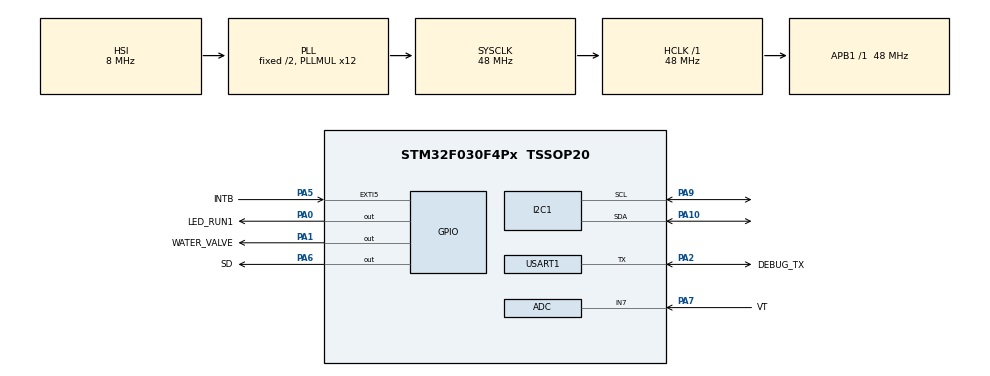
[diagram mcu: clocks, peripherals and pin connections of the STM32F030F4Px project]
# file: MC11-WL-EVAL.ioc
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Mcu.Family=STM32F0
Mcu.Name=STM32F030F4Px
Mcu.Package=TSSOP20
PA0.GPIO_Label=LED_RUN1
PA0.Signal=GPIO_Output
PA1.GPIO_Label=WATER_VALVE
PA1.Signal=GPIO_Output
PA10.Mode=I2C
PA10.Signal=I2C1_SDA
PA13.Mode=Serial_Wire
PA13.Signal=SYS_SWDIO
PA14.Mode=Serial_Wire
PA14.Signal=SYS_SWCLK
PA2.GPIO_Label=DEBUG_TX
PA2.Mode=Half_duplex(single_wire_mode)
PA2.Signal=USART1_TX
PA5.GPIO_Label=INTB
PA5.Signal=GPXTI5
PA6.GPIO_Label=SD
PA6.PinState=GPIO_PIN_SET
PA6.Signal=GPIO_Output
PA7.GPIO_Label=VT
PA7.Mode=IN7
PA7.Signal=ADC_IN7
PA9.Mode=I2C
PA9.Signal=I2C1_SCL
ProjectManager.HeapSize=0x200
ProjectManager.StackSize=0x400
ProjectManager.TargetToolchain=MDK-ARM V5
RCC.AHBFreq_Value=48000000
RCC.APB1Freq_Value=48000000
RCC.APB1TimFreq_Value=48000000
RCC.HCLKFreq_Value=48000000
RCC.PLLMUL=RCC_PLL_MUL12
RCC.SYSCLKFreq_VALUE=48000000
RCC.SYSCLKSource=RCC_SYSCLKSOURCE_PLLCLK
USART1.BaudRate=9600
USART1.VirtualMode-Half_duplex(single_wire_mode)=VM_ASYNC
board=custom

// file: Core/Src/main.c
/* USER CODE BEGIN Header */
/**
  ******************************************************************************
  * @file           : main.c
  * @brief          : Main program body
  ******************************************************************************
  * @attention
  *
  * Copyright (c) 2024 STMicroelectronics.
  * All rights reserved.
  *
  * This software is licensed under terms that can be found in the LICENSE file
  * in the root directory of this software component.
  * If no LICENSE file comes with this software, it is provided AS-IS.
  *
  ******************************************************************************
  */
/* USER CODE END Header */
#include "main.h"
#include "adc.h"
#include "i2c.h"
#include "usart.h"
#include "gpio.h"

/* USER CODE BEGIN Includes */
#include <stdio.h>
#include "mc11.h"
/* USER CODE END Includes */

/* USER CODE BEGIN PV */
/*打印开关print_en在MC11.h文件中定义，当前定义为0，打印功能关闭，定义为1打印功能开启*/
int wait_time=0;
float F0,F1,C;//通道0/1频率值，电容值
uint8_t result = 0;
/* USER CODE END PV */

void SystemClock_Config(void);

int main(void)
{

  /* MCU Configuration--------------------------------------------------------*/

  /* Reset of all peripherals, Initializes the Flash interface and the Systick. */
  HAL_Init();

  /* Configure the system clock */
  SystemClock_Config();

  /* Initialize all configured peripherals */
  MX_GPIO_Init();
  MX_ADC_Init();
  MX_I2C1_Init();
  MX_USART1_UART_Init();
  /* USER CODE BEGIN 2 */
  LED_RUN1_GPIO_Port->BSRR = LED_RUN1_Pin;

  // 给MC11的SD引脚（默认上拉的）低电平，让它工作
  SD_GPIO_Port->BSRR = SD_Pin << 16;
  HAL_Delay(1); // 启动时间20us

  result = MC11_Init(&wait_time); //MC11初始化配置，获取测量转换时间；
  if(!result) printf("MC11_Init failed\r\n");
  /* USER CODE END 2 */

  /* Infinite loop */
  /* USER CODE BEGIN WHILE */
  while (1)
  {
    result = MC11_Measure(&F0,&F1,&C,wait_time); //循环测量MC11频率/电容；
		if(result!=0){
      //printf("F0:%.3f Mhz F1:%.3f Mhz C:%.3f pF\r\n",F0, F1, C);
      printf("%.3f pF\n", C);
    }
  	HAL_Delay(200);
    /* USER CODE END WHILE */

  }
}

void SystemClock_Config(void)
{
  RCC_OscInitTypeDef RCC_OscInitStruct = {0};
  RCC_ClkInitTypeDef RCC_ClkInitStruct = {0};
  RCC_PeriphCLKInitTypeDef PeriphClkInit = {0};

  /** Initializes the RCC Oscillators according to the specified parameters
  * in the RCC_OscInitTypeDef structure.
  */
  RCC_OscInitStruct.OscillatorType = RCC_OSCILLATORTYPE_HSI|RCC_OSCILLATORTYPE_HSI14;
  RCC_OscInitStruct.HSIState = RCC_HSI_ON;
  RCC_OscInitStruct.HSI14State = RCC_HSI14_ON;
  RCC_OscInitStruct.HSICalibrationValue = RCC_HSICALIBRATION_DEFAULT;
  RCC_OscInitStruct.HSI14CalibrationValue = 16;
  RCC_OscInitStruct.PLL.PLLState = RCC_PLL_ON;
  RCC_OscInitStruct.PLL.PLLSource = RCC_PLLSOURCE_HSI;
  RCC_OscInitStruct.PLL.PLLMUL = RCC_PLL_MUL12;
  RCC_OscInitStruct.PLL.PREDIV = RCC_PREDIV_DIV1;
  if (HAL_RCC_OscConfig(&RCC_OscInitStruct) != HAL_OK)
  {
    Error_Handler();
  }

  /** Initializes the CPU, AHB and APB buses clocks
  */
  RCC_ClkInitStruct.ClockType = RCC_CLOCKTYPE_HCLK|RCC_CLOCKTYPE_SYSCLK
                              |RCC_CLOCKTYPE_PCLK1;
  RCC_ClkInitStruct.SYSCLKSource = RCC_SYSCLKSOURCE_PLLCLK;
  RCC_ClkInitStruct.AHBCLKDivider = RCC_SYSCLK_DIV1;
  RCC_ClkInitStruct.APB1CLKDivider = RCC_HCLK_DIV1;

  if (HAL_RCC_ClockConfig(&RCC_ClkInitStruct, FLASH_LATENCY_1) != HAL_OK)
  {
    Error_Handler();
  }
  PeriphClkInit.PeriphClockSelection = RCC_PERIPHCLK_USART1|RCC_PERIPHCLK_I2C1;
  PeriphClkInit.Usart1ClockSelection = RCC_USART1CLKSOURCE_PCLK1;
  PeriphClkInit.I2c1ClockSelection = RCC_I2C1CLKSOURCE_HSI;
  if (HAL_RCCEx_PeriphCLKConfig(&PeriphClkInit) != HAL_OK)
  {
    Error_Handler();
  }
}

void Error_Handler(void)
{
  __disable_irq();
  while (1)
  {
  }
}
